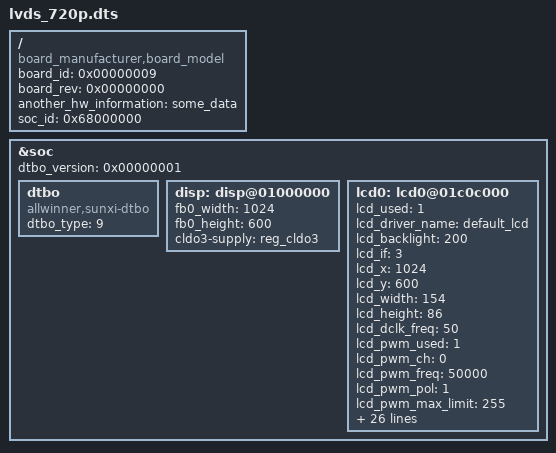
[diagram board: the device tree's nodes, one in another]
/dts-v1/;
/plugin/;

/ {

  compatible = "board_manufacturer,board_model";

  /* These properties are examples */
  board_id = <0x00000009>;
  board_rev = <0x00000000>;
  another_hw_information = "some_data";
  soc_id = <0x68000000>;

};

&soc {
	dtbo_version = <0x00000001>;
	dtbo{
		compatible = "allwinner,sunxi-dtbo";
		dtbo_type = <9>;
	};
	//twi0: twi@0x05002000{
	//	status = "okay";
	//};

	disp: disp@01000000 {
		fb0_width                = <1024>;
		fb0_height               = <600>;
		cldo3-supply = <&reg_cldo3>;
	};

//	gmac0: eth@05020000 {
//		status = "disabled";
//	};

	lcd0: lcd0@01c0c000 {
                        lcd_used            = <1>;

                        lcd_driver_name     = "default_lcd";//bp101wx1
                        lcd_backlight       = <200>;
                        lcd_if              = <3>; //lcd

                        lcd_x               = <1024>;
                        lcd_y               = <600>;
                        lcd_width           = <154>;
                        lcd_height          = <86>;
                        lcd_dclk_freq       = <50>;   // <70>

                        lcd_pwm_used        = <1>;
                        lcd_pwm_ch          = <0>;
                        lcd_pwm_freq        = <50000>;
                        lcd_pwm_pol         = <1>;
                        lcd_pwm_max_limit   = <255>;

                        lcd_hbp             = <160>;
                        lcd_ht              = <1324>;
                        lcd_hspw            = <116>;
                        lcd_vbp             = <24>;
                        lcd_vt              = <629>;
                        lcd_vspw            = <3>;

			lcd_lvds_if         = <0>;
                        lcd_lvds_colordepth = <0>;//0
                        lcd_lvds_mode       = <0>;
                        lcd_frm             = <0>;//0
                        lcd_hv_clk_phase    = <0>;
                        lcd_hv_sync_polarity= <0>;
                        lcd_gamma_en        = <0>;
                        lcd_bright_curve_en = <0>;
                        lcd_cmap_en         = <0>;
                        lcd_fsync_en        = <0>;
                        lcd_fsync_act_time  = <1000>;
                        lcd_fsync_dis_time  = <1000>;
                        lcd_fsync_pol       = <0>;

                        deu_mode            = <0>;
                        lcdgamma4iep        = <22>;
                        smart_color         = <90>;

                        lcd_pin_power = "bldo1";

                        lcd_power = "dc1sw";
                        //lcd_bl_en        = <&pio PD 28 1 0 3 1>;       

                        //lcd_gpio_0       = <&pio PH 4 1 0 3 1>;

                        pinctrl-0 = <&lvds0_pins_a>;
                        pinctrl-1 = <&lvds0_pins_b>;

	};
};
